# psc3m6 register map
Vendor: Infineon Technologies; Series: PSC3M6; File version: 1.0
CPU: CM33 r0p1, little endian, MPU, FPU, DSP, VTOR, 3 interrupt priority bits, 167 interrupts
Registers are 32-bit, read-write, reset 0x0 unless marked. A register's access mark holds for its fields unless they carry their own. Offsets are from the block's base; [hi:lo] are bit positions; lines under a group give offsets from that group; {n}, {i} and the like mark numbered series; 'fields as' and 'values as' point back to an identical list.

## IPC
Base 0x421D0000
{0x0+0x20*i} STRUCT[{i}] (i=0..3) group — IPC structure
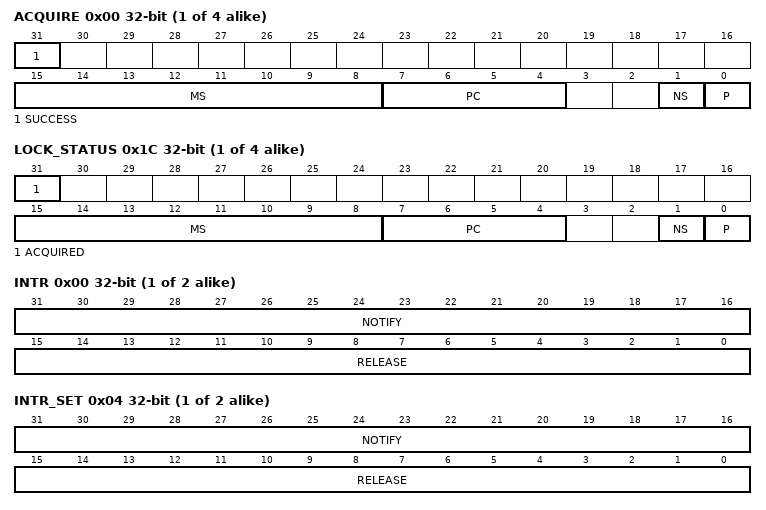
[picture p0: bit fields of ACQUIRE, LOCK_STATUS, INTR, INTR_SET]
  0x00 ACQUIRE ro (reset mask 0x80000000) — IPC acquire
    [31] SUCCESS
    [15:8] MS — This field specifies the bus master identifier that successfully acquired the lock.
    [7:4] PC
    [1] NS
    [0] P
  0x04 RELEASE wo — IPC release
    [15:0] INTR_RELEASE — Writing this field releases a lock and allows for the generation of release events to the IPC interrupt structures, but only when the lock is acquired (LOCK_STATUS.ACQUIRED is '1'). The IPC release cause fields associated with this IPC structure are set to '1', but only for those IPC interrupt structures for which the corresponding bit field in INTR_RELEASE[] is set to '1'. SW writes a '1' to the bit fields to generate a release event. Due to the transient nature of this event, SW always reads a '0' from this field.
  0x08 NOTIFY wo — IPC notification
    [15:0] INTR_NOTIFY — This field allows for the generation of notification events to the IPC interrupt structures. The IPC notification cause fields associated with this IPC structure are set to '1', but only for those IPC interrupt structures for which the corresponding bit field in INTR_NOTIFY[] is set to '1'. SW writes a '1' to the bit fields to generate a notify event. Due to the transient nature of this event, SW always reads a '0' from this field.
  0x0C DATA0 reset not defined — IPC data 0
    [31:0] DATA — This field holds a 32-bit data element that is associated with the IPC structure.
  0x10 DATA1 reset not defined — IPC data 1
    fields as STRUCT[0].DATA0
  0x1C LOCK_STATUS ro (reset mask 0x80000000) — IPC lock status
    [31] ACQUIRED
    [15:8] MS — This field specifies the bus master identifier that successfully acquired the lock.
    [7:4] PC
    [1] NS
    [0] P
{0x1000+0x20*i} INTR_STRUCT[{i}] (i=0..1) group — IPC interrupt structure
  0x00 INTR — Interrupt
    [31:16] NOTIFY write-1-clears — These interrupt cause fields are activated (HW sets the field to '1') when a IPC notification event is detected. One bit field for each master. SW writes a '1' to these field to clear the interrupt cause.
    [15:0] RELEASE write-1-clears — These interrupt cause fields are activated (HW sets the field to '1') when a IPC release event is detected. One bit field for each master. SW writes a '1' to these field to clear the interrupt cause.
  0x04 INTR_SET — Interrupt set
    [31:16] NOTIFY write-1-sets — SW writes a '1' to this field to set the corresponding field in the INTR register.
    [15:0] RELEASE write-1-sets — SW writes a '1' to this field to set the corresponding field in the INTR register.
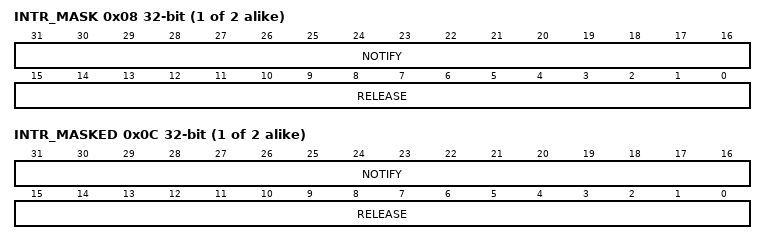
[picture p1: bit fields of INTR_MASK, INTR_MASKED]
  0x08 INTR_MASK — Interrupt mask
    [31:16] NOTIFY — Mask bit for corresponding field in the INTR register.
    [15:0] RELEASE — Mask bit for corresponding field in the INTR register.
  0x0C INTR_MASKED ro — Interrupt masked
    [31:16] NOTIFY — Logical and of corresponding INTR and INTR_MASK fields.
    [15:0] RELEASE — Logical and of corresponding request and mask bits.

## MXCORDIC_1_1
Base 0x42240000
0x00 CTL
  [31] ENABLED — Enables/Disables IP
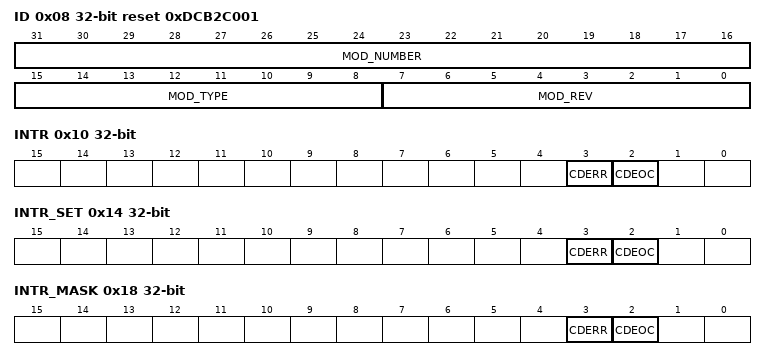
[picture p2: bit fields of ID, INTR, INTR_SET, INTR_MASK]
0x08 ID ro reset 0xDCB2C001 — Module Identification Register
  [31:16] MOD_NUMBER — Module Number Value - MOD_NUMBER
  [15:8] MOD_TYPE — Module Type - MOD_TYPE
  [7:0] MOD_REV — Module Revision Number - MOD_REV
0x10 INTR — Interrupt Cause Register
  [3] CDERR write-1-clears — CORDIC Error Event Flag - CDERR. This bitfield will preserve interrupt cause status also when IP is disabled. By writing '0' to CTL.ENABLED bitfield will not be reset.
  [2] CDEOC write-1-clears — CORDIC End of Calculation Event Flag - CDEOC. This bitfield will preserve interrupt cause status also when IP is disabled. By writing '0' to CTL.ENABLED bitfield will not be reset.
0x14 INTR_SET — Interrupt Set Register
  [3] CDERR write-1-sets — CORDIC Error Event Flag Set - CDERR
  [2] CDEOC write-1-sets — CORDIC Event Flag Set - CDEOC
0x18 INTR_MASK — Interrupt Mask Register
  [3] CDERR — CORDIC Error Interrupt Mask - CDERR
  [2] CDEOC — CORDIC End of Calculation Interrupt Mask- CDEOC
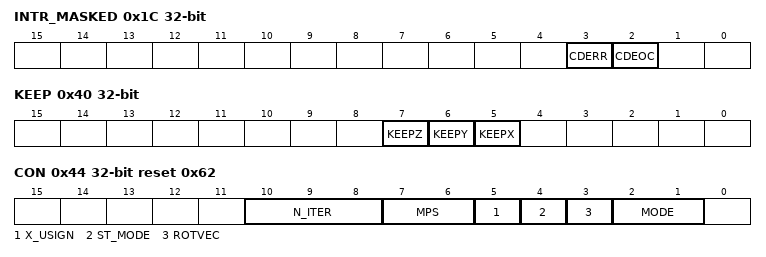
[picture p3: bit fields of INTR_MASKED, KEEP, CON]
0x1C INTR_MASKED ro — Interrupt Masked Register
  [3] CDERR — CORDIC Error Interrupt Masked - CDERR
  [2] CDEOC — CORDIC End of Calculation Interrupt Masked- CDEOC
0x40 KEEP — CORDIC Keep Register
  [7] KEEPZ — Last Z Result as Initial Data for New Calculation - KEEPZ
  [6] KEEPY — Last Y Result as Initial Data for New Calculation - KEEPY
  [5] KEEPX — Last X Result as Initial Data for New Calculation - KEEPX
0x44 CON reset 0x62 — CORDIC Control Register
  [10:8] N_ITER — Number of CORDIC iterations divided by 4
    {v}=N/A (v=1..7)
  [7:6] MPS — X and Y Magnitude Prescaler - MPS
    0=DIVIDE_BY_1 (N/A); 1=DIVIDE_BY_2 (N/A); 2=DIVIDE_BY_4 (N/A); 3=RSVD (N/A)
  [5] X_USIGN — Result Data Format for X in Circular Vectoring Mode - X_USIGN
    0=SIGNED (N/A); 1=UNSIGNED (N/A)
  [4] ST_MODE — Start Method - ST_MODE
    0=AUTO (Operation starts with write into CORDZ register); 1=ST (Operation starts with write into START_CMD register)
  [3] ROTVEC — Rotation Vectoring Selection - ROTVEC
    0=VECTORING (N/A); 1=ROTATION (N/A)
  [2:1] MODE — Operating Mode - MODE
    0=LINEAR (N/A); 1=CIRCULAR (N/A); 2=RSVD (N/A); 3=HYPERBOLIC (N/A)
0x48 CORDX — CORDIC X Data Register
  [31:8] DATA — Initial X Parameter Data - DATA
0x4C CORDY — CORDIC Y Data Register
  [31:8] DATA — Initial Y Parameter Data - DATA
0x50 CORDZ — CORDIC Z Data Register
  [31:8] DATA — Initial Z Parameter Data - DATA
0x54 CORRX ro — CORDIC X Result Register
  [31:8] RESULT — X Calculation Result - RESULT
0x58 CORRY ro — CORDIC Y Result Register
  [31:8] RESULT — Y Calculation Result - RESULT
0x5C CORRZ ro — CORDIC Z Result Register
  [31:8] RESULT — Z Calculation Result - RESULT
0x60 STAT ro — CORDIC Status Register
  [0] BSY — Busy Indication - BSY
0x64 START_CMD — CORDIC Start Command Register
  [0] ST — Start Calculation Set - ST
